# PIC32CZ2038CA70100 device description
Architecture: CORTEX-M7; Family: PIC32CZ; Series: CA70
Registers are 32-bit, read-write, no defined reset value unless marked. A register's access mark holds for its fields unless they carry their own. Offsets are from the block's base; [hi:lo] are bit positions; {n}, {i} and the like mark numbered series.

## UTMI — USB Transmitter Interface Macrocell
Instances: UTMI 0x400E0400
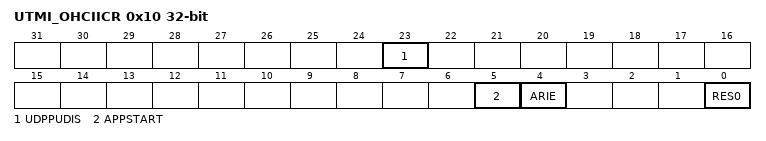
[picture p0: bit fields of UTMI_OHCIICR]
0x10 UTMI_OHCIICR — OHCI Interrupt Configuration Register
  [23] UDPPUDIS — USB Device Pull-up Disable
  [5] APPSTART — Reserved
  [4] ARIE — OHCI Asynchronous Resume Interrupt Enable
  [0] RES0 — USB PORTx Reset
0x30 UTMI_CKTRIM — UTMI Clock Trimming Register
  [1:0] FREQ — UTMI Reference Clock Frequency
    0=XTAL12 (12 MHz reference clock); 1=XTAL16 (16 MHz reference clock)

## WDT — Watchdog Timer
Instances: WDT 0x400E1850
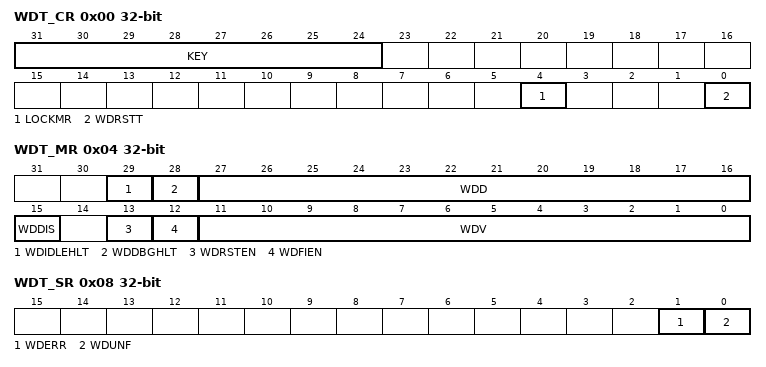
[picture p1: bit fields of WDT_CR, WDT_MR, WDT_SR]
0x00 WDT_CR wo — Control Register
  [31:24] KEY — Password
    165=PASSWD (Writing any other value in this field aborts the write operation.)
  [4] LOCKMR — Lock Mode Register Write Access
  [0] WDRSTT — Watchdog Restart
0x04 WDT_MR — Mode Register
  [29] WDIDLEHLT — Watchdog Idle Halt
  [28] WDDBGHLT — Watchdog Debug Halt
  [27:16] WDD — Watchdog Delta Value
  [15] WDDIS — Watchdog Disable
  [13] WDRSTEN — Watchdog Reset Enable
  [12] WDFIEN — Watchdog Fault Interrupt Enable
  [11:0] WDV — Watchdog Counter Value
0x08 WDT_SR ro — Status Register
  [1] WDERR — Watchdog Error (cleared on read)
  [0] WDUNF — Watchdog Underflow (cleared on read)

## GPNVMBITS (FUSES module)
Instances: GPNVMBITS 0 in fuses
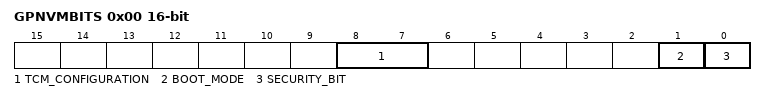
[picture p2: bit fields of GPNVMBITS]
0x00 GPNVMBITS 16-bit
  [8:7] TCM_CONFIGURATION
  [1] BOOT_MODE — Boot Mode Selection
  [0] SECURITY_BIT ro

## LOCKBIT
Instances: LOCKBIT 0 in lockbits
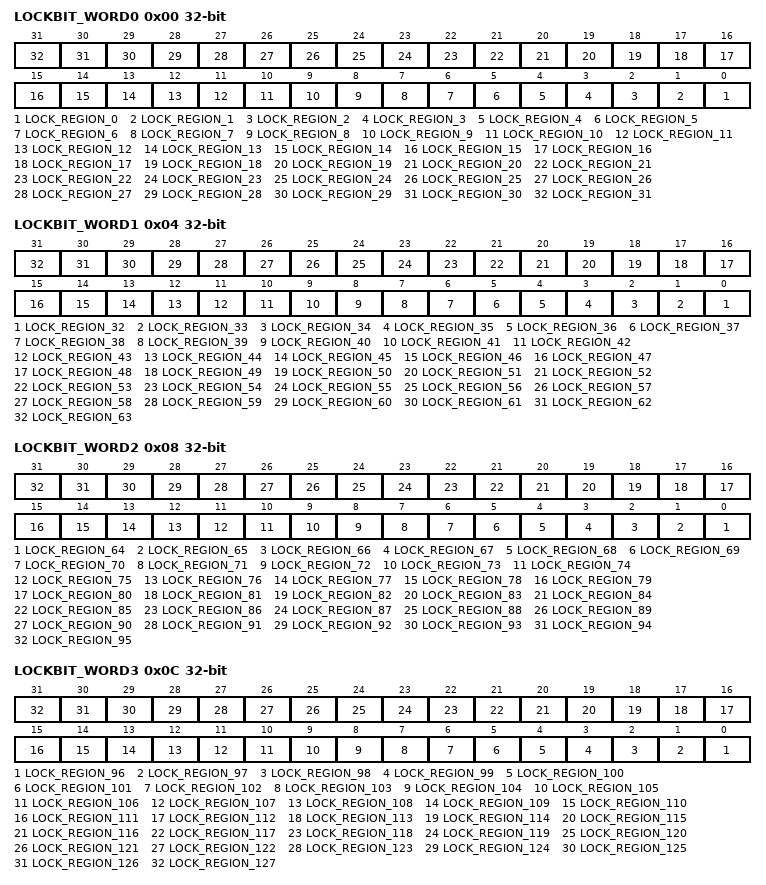
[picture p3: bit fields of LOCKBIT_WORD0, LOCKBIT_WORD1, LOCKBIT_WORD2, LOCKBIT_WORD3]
0x00 LOCKBIT_WORD0 — Lock Bits Word 0
  [n] LOCK_REGION_{n} (n=0..31)
0x04 LOCKBIT_WORD1 — Lock Bits Word 1
  [n-32] LOCK_REGION_{n} (n=32..63)
0x08 LOCKBIT_WORD2 — Lock Bits Word 2
  [n-64] LOCK_REGION_{n} (n=64..95)
0x0C LOCKBIT_WORD3 — Lock Bits Word 3
  [n-96] LOCK_REGION_{n} (n=96..127)

## SysTick — System timer
Instances: SysTick 0xE000E010
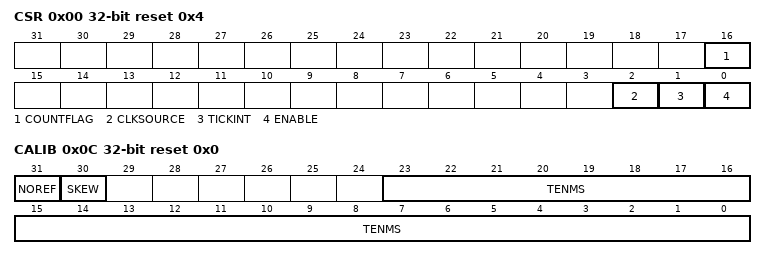
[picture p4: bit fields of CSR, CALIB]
0x00 CSR access not given reset 0x4 — SysTick Control and Status Register
  [16] COUNTFLAG
  [2] CLKSOURCE
    0=external clock; 1=processor clock
  [1] TICKINT
    0=counting down to 0 does not assert the SysTick exception request; 1=counting down to 0 asserts the SysTick exception request
  [0] ENABLE
    0=counter disabled; 1=counter enabled
0x04 RVR access not given reset 0x0 — SysTick Reload Value Register
  [23:0] RELOAD — Value to load into the SysTick Current Value Register when the counter reaches 0
0x08 CVR access not given reset 0x0 — SysTick Current Value Register
  [23:0] CURRENT — Current value at the time the register is accessed
0x0C CALIB access not given reset 0x0 — SysTick Calibration Value Register
  [31] NOREF
    0=The reference clock is provided; 1=The reference clock is not provided
  [30] SKEW
    0=10ms calibration value is exact; 1=10ms calibration value is inexact, because of the clock frequency
  [23:0] TENMS — Reload value to use for 10ms timing

## NVIC — Nested Vectored Interrupt Controller
Instances: NVIC 0xE000E100
{0x0+4i} NVICISER{i} access not given reset 0x0 (i=0..3) — Interrupt Set Enable Register n
  [31:0] SETENA — Interrupt set enable bits
{0x80+4i} NVICICER{i} access not given reset 0x0 (i=0..3) — Interrupt Clear Enable Register n
  [31:0] CLRENA — Interrupt clear-enable bits
{0x100+4i} NVICISPR{i} access not given reset 0x0 (i=0..3) — Interrupt Set Pending Register n
  [31:0] SETPEND — Interrupt set-pending bits
{0x180+4i} NVICICPR{i} access not given reset 0x0 (i=0..3) — Interrupt Clear Pending Register n
  [31:0] CLRPEND — Interrupt clear-pending bits
{0x200+4i} NVICIABR{i} access not given reset 0x0 (i=0..3) — Interrupt Active bit Register n
  [31:0] ACTIVE — Interrupt active flags
{0x300+i} NVICIP{i} 8-bit access not given reset 0x0 (i=0..105) — Interrupt Priority Register n
  [7:0] PRI{i} — Priority of interrupt {i}
0xE00 NVICSTIR access not given reset 0x0 — Software Trigger Interrupt Register
  [8:0] INTID — Interrupt ID of the interrupt to trigger, in the range 0-239. For example, a value of 0x03 specifies interrupt IRQ3.

## MPU — Memory Protection Unit
Instances: MPU 0xE000ED90
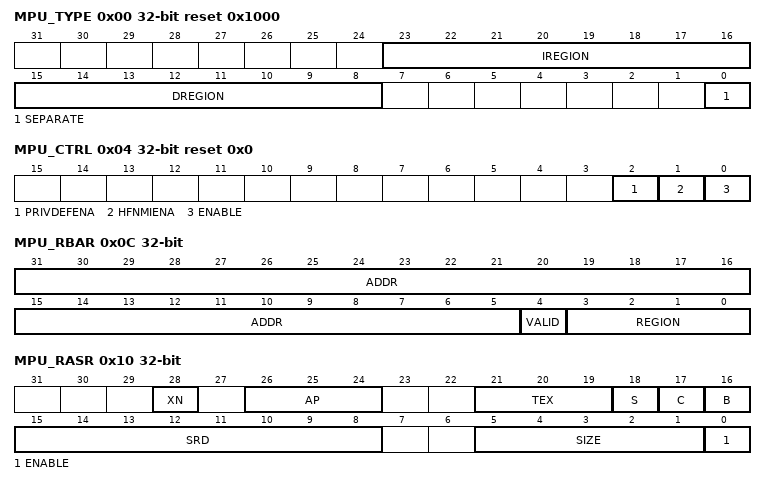
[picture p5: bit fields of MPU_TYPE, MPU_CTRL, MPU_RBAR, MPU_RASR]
0x00 MPU_TYPE access not given reset 0x1000
  [23:16] IREGION — Indicates the number of supported MPU data regions.
  [15:8] DREGION — Indicates the number of supported MPU instruction regions.
  [0] SEPARATE — Indicates support for unified or separate instruction and date memory maps.
0x04 MPU_CTRL access not given reset 0x0 — MPU Control Register
  [2] PRIVDEFENA — Enables privileged software access to the default memory map.
  [1] HFNMIENA — Enables the operation of MPU during hard fault, NMI, and FAULTMASK handlers.
  [0] ENABLE — Enables the MPU
0x08 MPU_RNR access not given — MPU Region Number Register
  [7:0] REGION — Indicates the MPU region referenced by the MPU_RBAR and MPU_RASR registers.
0x0C MPU_RBAR access not given — MPU Region Base Address Register
  [31:5] ADDR — Region base address field.
  [4] VALID — MPU Region Number valid bit.
  [3:0] REGION — MPU region field.
0x10 MPU_RASR access not given — MPU Region Attribute and Size Register
  [28] XN — Instruction access disable bit.
  [26:24] AP — Access permission field.
  [21:19] TEX — MPU access permission attributes.
  [18] S — Shareable bit.
  [17] C — MPU access permission attributes.
  [16] B — MPU access permission attributes.
  [15:8] SRD — Subregion disable bits.
  [5:1] SIZE — Specifies the size of the MPU protection region.
  [0] ENABLE — Region enable bit.

## FPU — Floating Point Unit
Instances: FPU 0xE000EF34
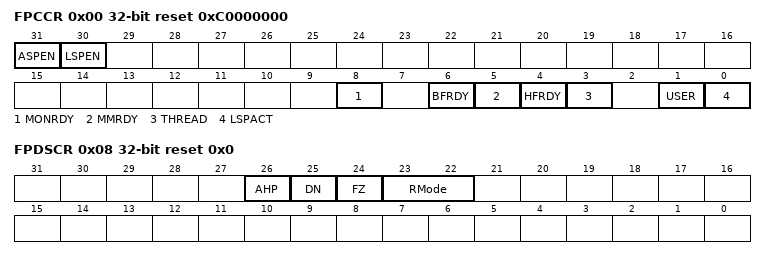
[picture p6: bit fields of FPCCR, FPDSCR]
0x00 FPCCR access not given reset 0xC0000000 — Floating-point Context Control Register
  [31] ASPEN — Enables CONTROL.FPCA setting on execution of a floating-point instruction. This results in automatic hardware state preservation and restoration, for floating-point context, on exception entry and exit.
  [30] LSPEN — Enable automatic lazy state preservation for floating-point context.
  [8] MONRDY — DebugMonitor is enabled and priority permits setting MON_PEND when the floating-point stack frame was allocated.
  [6] BFRDY — BusFault is enabled and priority permitted setting the BusFault handler to the pending state when the floating-point stack frame was allocated.
  [5] MMRDY — MemManage is enabled and priority permitted setting the MemManage handler to the pending state when the floating-point stack frame was allocated.
  [4] HFRDY — Priority permitted setting the HardFault handler to the pending state when the floating-point stack frame was allocated.
  [3] THREAD — Mode was Thread Mode when the floating-point stack frame was allocated.
  [1] USER — Privilege level was user when the floating-point stack frame was allocated.
  [0] LSPACT — Lazy state preservation is active. Floating-point stack frame has been allocated but saving state to it has been deferred.
0x04 FPCAR access not given — Floating-point Context Address Register
  [31:3] ADDRESS — The location of the unpopulated floating-point register space allocated on an exception stack frame.
0x08 FPDSCR access not given reset 0x0 — Floating-point Default Status Control Register
  [26] AHP — Default value for FPSCR.AHP.
  [25] DN — Default value for FPSCR.DN.
  [24] FZ — Default value for FPSCR.FZ.
  [23:22] RMode — Default value for FPSCR.RMode.
